CM_ "IMPORT _toyota_2017.dbc";
CM_ "IMPORT _comma.dbc";
CM_ "IMPORT _toyota_nodsu_common.dbc";

BO_ 705 GAS_PEDAL: 8 XXX
 SG_ GAS_RELEASED : 3|1@0+ (1,0) [0|1] "" XXX
 SG_ GAS_PEDAL : 55|8@0+ (0.005,0) [0|1] "" XXX

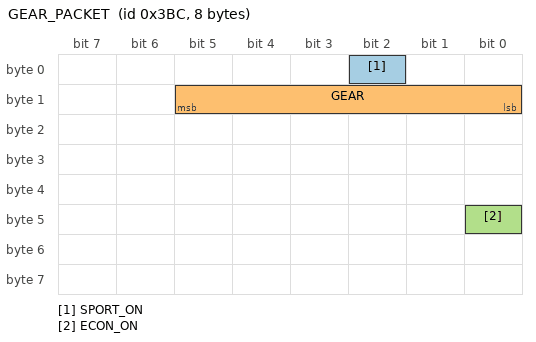
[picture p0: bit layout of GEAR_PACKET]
BO_ 956 GEAR_PACKET: 8 XXX
 SG_ SPORT_ON : 2|1@0+ (1,0) [0|1] "" XXX
 SG_ GEAR : 13|6@0+ (1,0) [0|63] "" XXX
 SG_ ECON_ON : 40|1@0+ (1,0) [0|1] "" XXX

VAL_ 956 GEAR 0 "D" 1 "S" 8 "N" 16 "R" 32 "P";
VAL_ 956 SPORT_ON 0 "off" 1 "on";
VAL_ 956 ECON_ON 0 "off" 1 "on";
